# DPLL_HDMI_L4_CFG register map
Vendor: Texas Instruments
Peripheral module from a debugger description file (folder DRA74xP_75xP_76xP_77xP).
Registers are 32-bit, access per field, reset 0x0 unless marked. A register's access mark holds for its fields unless they carry their own. Offsets are as the file gives them; lines under a group give offsets from that group; [hi:lo] are bit positions; {n}, {i} and the like mark numbered series; 'fields as' and 'values as' point back to an identical list; <NAME> marks a mode.

## DPLL_HDMI_L4_CFG
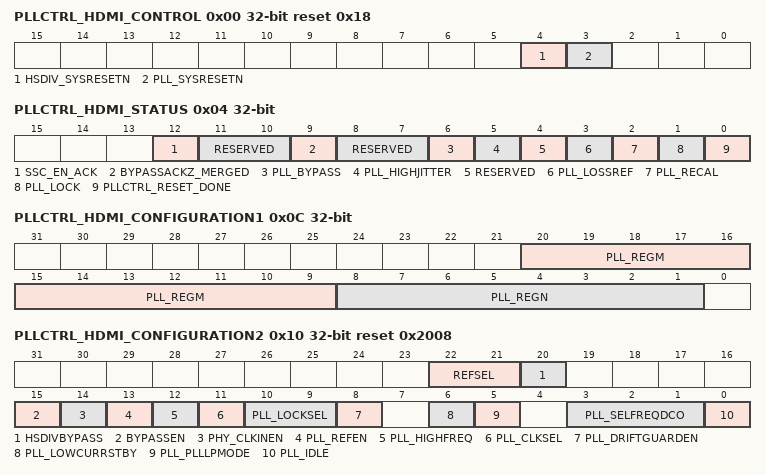
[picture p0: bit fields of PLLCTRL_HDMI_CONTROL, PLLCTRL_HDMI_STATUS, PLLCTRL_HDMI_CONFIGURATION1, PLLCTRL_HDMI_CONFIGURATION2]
0x00 PLLCTRL_HDMI_CONTROL reset 0x18 — This register controls the PLL reset/power and modes
  [4] HSDIV_SYSRESETN rw — Force HSDIVIDER SYSRESETN.
    0=HSDIV_SYSRST_ACT (HSDIVIDER SYSRESET forced active); 1=HSDIV_OP (HSDIVIDER SYSRESET controlled by power FSM)
  [3] PLL_SYSRESETN rw — Force SYSRESETN.
    0=PLL_SYSRST_ACT (DPLL_HDMI SYSRESET forced active); 1=PLL_OP (DPLL_HDMI SYSRESET controlled by power FSM)
0x04 PLLCTRL_HDMI_STATUS ro — This register contains the status information
  [12] SSC_EN_ACK — Spread Spectrum Clocking acknowledgeNote: SSC feature is not supported enum=SSC_ACT .
    0=SSC_INACT (Spread Spectrum Clocking inactive); 1=SSC_INACT (Spread Spectrum Clocking active)
  [11:10] RESERVED — Read returns zero.
  [9] BYPASSACKZ_MERGED — Merged state of bypass mode on HDMI_PHY
    0=BYPASS_ACK (HDMI_PHY has switched to using the bypass clocks.); 1=BYPASS_NAK (DPLL_HDMI outputs are still being used by the HDMI_PHY)
  [8:7] RESERVED — Read returns zero.
  [6] PLL_BYPASS — DPLL_HDMI Bypass status
    0=BYPASS_IN (DPLL_HDMI not bypassing); 1=BYPASS_ACT (DPLL_HDMI bypass)
  [5] PLL_HIGHJITTER — DPLL_HDMI High Jitter status
    0=NORMAL_JITTER (DPLL_HDMI in normal jitter condition); 1=HIGH_JIITTER (DPLL_HDMI in high jitter condition: Phase error 24%)
  [4] RESERVED — Read returns zero.
  [3] PLL_LOSSREF — DPLL_HDMI Reference Loss status
    0=REF_INP_ACT (Reference input active); 1=REF_INP_INACT (Reference input inactive)
  [2] PLL_RECAL — DPLL_HDMI re-calibration status If this bit is active, the DPLL_HDMI needs to be re-calibrated
    0=RECAL_NOT_REQUIRED (Recalibration is not required); 1=RECAL_REQUIRED (Recalibration is required)
  [1] PLL_LOCK — DPLL_HDMI Lock status See the programming guide for the use of this bit
    0=DSI_PLL_NOLOCK (DPLL_HDMI is not locked); 1=DSI_PLL_LOCK (DPLL_HDMI is locked)
  [0] PLLCTRL_RESET_DONE — DPLL_HDMI reset done status
    0=NOTRD (Reset is in progress); 1=RDONE (Reset has completed)
0x08 PLLCTRL_HDMI_GO — This register contains the GO bit
  [0] PLL_GO rw — Request (re-)locking sequence of the DPLL_HDMI. If the AutoMode bit is set, then this will be deferred until DISPC Update Sync goes active
    0=DONE (No pending action); 1=GO (Request DPLL_HDMI (re-)locking/locking pending)
0x0C PLLCTRL_HDMI_CONFIGURATION1 — This register contains the latched PLL and HSDIVDER configuration bits
  [20:9] PLL_REGM rw — M Divider for DPLL_HDMI.
  [8:1] PLL_REGN rw — N Divider for DPLL_HDMI (Reference). Divider value = PLL_REGN+1.
0x10 PLLCTRL_HDMI_CONFIGURATION2 reset 0x2008 — This register contains the unlatched PLL and HSDIVDER configuration bits These bits are 'shadowed' when automatic mode is selected
  [22:21] REFSEL rw — Selects the reference clock with optional divide by 2
    0=REF_PCLK (Select PCLK reference); 1=REF_1 (Select REF1 reference); 3=REF_SYSCLK (Select SYSCLK reference); 2=REF_2 (Select REF2 Reference)
  [20] HSDIVBYPASS rw — Forces HSDIVIDER to bypass mode
    0=HSDIV_NORMAL (HSDIVIDER in normal operation. Bypass controlled by DPLL_HDMI); 1=HSDIV_FORCE_BYP (HSDIVIDER forced to bypass mode.)
  [15] BYPASSEN rw — Selects sub-system functional clock as PHY clock source
    0=CLK_PLL (DPLL_HDMI controls the PHY clock source: PLL DCO if DPLL_HDMI is locked Sub-system functional clock if not locked); 1=CLK_BYPASS (Force sub-system functional clock to be used as the PHY clock source)
  [14] PHY_CLKINEN rw — PHY clock control
    0=PHY_CLK_DIS (PHY clock is disabled); 1=PHY_CLK_EN (PHY clock is enabled)
  [13] PLL_REFEN rw — DPLL_HDMI reference clock control
    0=REF_DIS (DPLL_HDMI reference clock disabled); 1=REF_EN (DPLL_HDMI reference clock enabled)
  [12] PLL_HIGHFREQ rw — Enables a division of pixel clock by 2 before input to the DPLL_HDMI Required for pixel clock frequencies above 32 MHz (21 MHZ if N = 0)
    0=DIV_BY_1 (Pixel clock is not divided); 1=DIV_BY_2 (Pixel clock is divided by 2)
  [11] PLL_CLKSEL rw — Reference clock selection
    0=SYSCLK_REF (Selects SYSCLK as DPLL_HDMI reference clock); 1=PCLK_REF (Selects Pixel Clock (PCLK) as DPLL_HDMI reference clock)
  [10:9] PLL_LOCKSEL rw — Selects the lock criteria for the DPLL_HDMI
    0=PHASELOCK; 1=FREQLOCK (Frequency Lock); 2=SPARE
  [8] PLL_DRIFTGUARDEN rw — DPLL_HDMI DRIFTGUARDEN
    0=DRIFT_GUARD_DIS (Only RECAL flag is asserted in case of temperature drift. The programmer should take appropriate action.); 1=DRIFT_GUARD_EN (Temperature drift will initiate automatic recalibration. RECAL flag will be asserted while this is taking place.)
  [6] PLL_LOWCURRSTBY rw — DPLL_HDMI LOW CURRENT STANDBY
    0=LOWCURRSTBY_NOTSEL (LOWCURRSTBY is not selected); 1=LOWCURRSTBY_SEL (LOWCURRSTBY is selected)
  [5] PLL_PLLLPMODE rw — Select the power / performance of the DPLL_HDMI
    0=FULL_PERF (Full performance, minimised jitter); 1=REDUCE_PERF (Reduced power, increased jitter)
  [3:1] PLL_SELFREQDCO rw — DCO frequency range selector for DPLL_HDMIOthers: Reserved .
    2=DCO_2 (Set if DCO frequency is between 750MHz and 1500MHz); 4=DCO_4 (Set if DCO frequency is between 1250MHz and 2500MHz)
  [0] PLL_IDLE rw — DPLL_HDMI IDLE:
    0=IDLE_NOTSEL (IDLE is not selected); 1=IDLE_SEL (IDLE is selected)
0x14 PLLCTRL_HDMI_CONFIGURATION3 — HSDIVIDER configuration bits for the M5 and M6 dividers
  [17:10] PLL_SD rw — Sigma delta divider setting for DPLL_HDMI based on the DPLL_HDMI lock configuration.
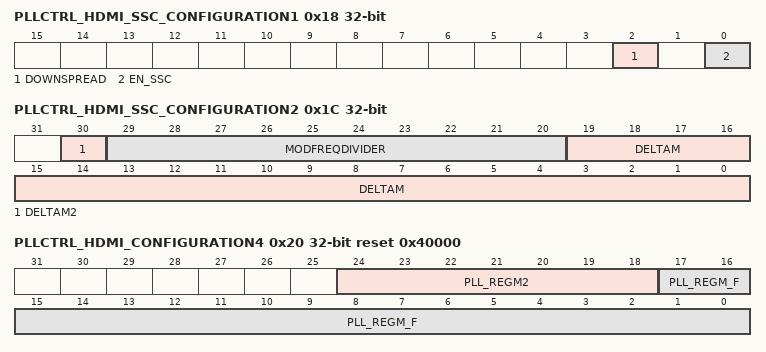
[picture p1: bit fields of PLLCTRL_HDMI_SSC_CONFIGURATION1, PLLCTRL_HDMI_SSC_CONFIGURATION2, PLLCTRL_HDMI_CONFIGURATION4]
0x18 PLLCTRL_HDMI_SSC_CONFIGURATION1 — Configuration for PLL Spread Spectrum Clocking modulation. Note: SSC feature is not supported.
  [2] DOWNSPREAD rw — Forces the clock spreading only in the down spectrum.
    0=NOTFORCED (Clock spreading not forced.); 1=FORCEDOWN (Spectrum spreading only in down direction.)
  [0] EN_SSC rw — Spread Spectrum Clocking enable
    0=SSC_OFF (Spread Spectrum Clocking disabled); 1=SSC_ON (Spread Spectrum Clocking enabled)
0x1C PLLCTRL_HDMI_SSC_CONFIGURATION2 — Note: SSC feature is not supported.
  [30] DELTAM2 rw — MSB of DeltaM control bus.
  [29:20] MODFREQDIVIDER rw — Modulation Frequency Divider (ModFreqDivider) control for dithering.The ModFreqDivider is split into Mantissa and 2(ModFreqDivider = ModFreqDividerMantissa * 2).Bits [29:23] define the Mantissa . Bits [22:20] define the Exponent .
  [19:0] DELTAM rw — DeltaM control for dithering. Split into integer and fractional part.Bits [19:18] define the integer part . Bits [17:0] define the fractional part .
0x20 PLLCTRL_HDMI_CONFIGURATION4 reset 0x40000 — Allows setting the fractional M divider and M2 divider for PLL.
  [24:18] PLL_REGM2 rw — M2 divider to configure DPLL_HDMI M2 divider factor.
  [17:0] PLL_REGM_F rw — Fractional part of M divider.
